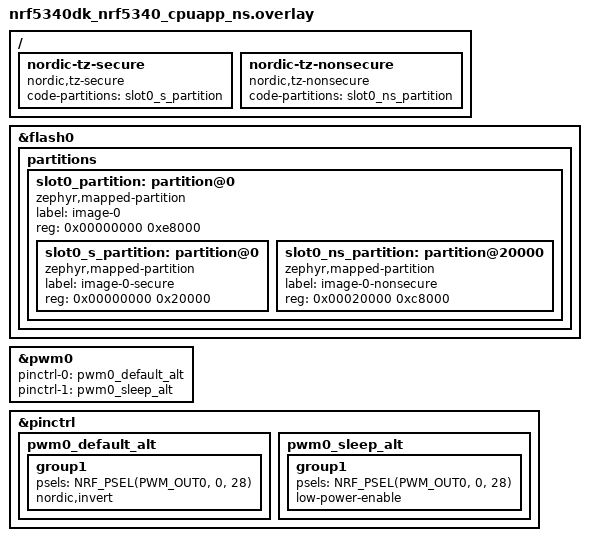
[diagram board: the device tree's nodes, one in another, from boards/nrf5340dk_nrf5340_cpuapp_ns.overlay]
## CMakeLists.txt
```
#
# Copyright (c) 2020 Nordic Semiconductor ASA
#
# SPDX-License-Identifier: LicenseRef-Nordic-5-Clause
#
cmake_minimum_required(VERSION 3.20.0)

find_package(Zephyr REQUIRED HINTS $ENV{ZEPHYR_BASE})
project(bluetooth_mesh_light_ctrl)

# NORDIC SDK APP START
target_sources(app PRIVATE
  src/main.c
  src/model_handler.c
  src/lc_pwm_led.c
)
target_include_directories(app PRIVATE include)
# NORDIC SDK APP END
```

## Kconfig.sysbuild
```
#
# Copyright (c) 2023 Nordic Semiconductor
#
# SPDX-License-Identifier: LicenseRef-Nordic-5-Clause
#

config PARTITION_MANAGER
	default n

config NRF_DEFAULT_IPC_RADIO
	default y

source "share/sysbuild/Kconfig"
```

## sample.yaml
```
sample:
  description: Bluetooth Mesh light fixture sample
  name: Bluetooth Mesh light fixture
common:
  tags:
    - bluetooth
    - ci_build
    - sysbuild
    - ci_samples_bluetooth
tests:
  sample.bluetooth.mesh.light_ctrl:
    sysbuild: true
    build_only: true
    integration_platforms:
      - nrf54l15dk/nrf54l15/cpuapp
    platform_allow:
      - nrf5340dk/nrf5340/cpuapp
      - nrf5340dk/nrf5340/cpuapp/ns
      - nrf54l15dk/nrf54l15/cpuapp
      - nrf54l15dk/nrf54l10/cpuapp
      - nrf54l15dk/nrf54l05/cpuapp
      - nrf54lm20dk/nrf54lm20a/cpuapp
  sample.bluetooth.mesh.light_ctrl.emds:
    sysbuild: true
    build_only: true
    integration_platforms:
      - nrf54l15dk/nrf54l15/cpuapp
    platform_allow:
      - nrf5340dk/nrf5340/cpuapp
      - nrf5340dk/nrf5340/cpuapp/ns
      - nrf54l15dk/nrf54l15/cpuapp
      - nrf54l15dk/nrf54l10/cpuapp
      - nrf54l15dk/nrf54l05/cpuapp
      - nrf54lm20dk/nrf54lm20a/cpuapp
    extra_args: FILE_SUFFIX=emds
  sample.bluetooth.mesh.light_ctrl.settings_ext_flash:
    sysbuild: true
    build_only: true
    integration_platforms:
      - nrf54l15dk/nrf54l15/cpuapp
    platform_allow:
      - nrf54l15dk/nrf54l15/cpuapp
      - nrf54l15dk/nrf54l10/cpuapp
      - nrf54l15dk/nrf54l05/cpuapp
    extra_args: FILE_SUFFIX=settings_ext_flash
```

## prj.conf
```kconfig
#
# Copyright (c) 2020 Nordic Semiconductor ASA
#
# SPDX-License-Identifier: LicenseRef-Nordic-5-Clause
#
CONFIG_NCS_SAMPLES_DEFAULTS=y

# Deferred logging helps improve LPN power consumption
# when friendship is established.
CONFIG_LOG_MODE_DEFERRED=y

# General configuration
CONFIG_NCS_APPLICATION_BOOT_BANNER_STRING="Mesh Light Fixture"
CONFIG_SYSTEM_WORKQUEUE_STACK_SIZE=2048
CONFIG_FLASH=y
CONFIG_FLASH_MAP=y
CONFIG_NVS=y
CONFIG_NVS_LOOKUP_CACHE=y
CONFIG_SETTINGS=y
CONFIG_SETTINGS_NVS_NAME_CACHE=y
CONFIG_HWINFO=y
CONFIG_DK_LIBRARY=y
CONFIG_PWM=y
CONFIG_SOC_FLASH_NRF_PARTIAL_ERASE=y

# Bluetooth configuration
CONFIG_BT=y
CONFIG_BT_DEVICE_NAME="Mesh Light Fixture"
CONFIG_BT_L2CAP_TX_BUF_COUNT=8
CONFIG_BT_OBSERVER=y
CONFIG_BT_PERIPHERAL=y

# Disable unused Bluetooth features
CONFIG_BT_CTLR_LE_ENC=n
CONFIG_BT_PHY_UPDATE=n
CONFIG_BT_CTLR_CHAN_SEL_2=n
CONFIG_BT_CTLR_MIN_USED_CHAN=n
CONFIG_BT_CTLR_PRIVACY=n

# Bluetooth Mesh configuration
CONFIG_BT_MESH=y
CONFIG_BT_MESH_RELAY=y
CONFIG_BT_MESH_FRIEND=y
CONFIG_BT_MESH_TX_SEG_MAX=10
CONFIG_BT_MESH_PB_GATT=y
CONFIG_BT_MESH_PROXY_USE_DEVICE_NAME=y
CONFIG_BT_MESH_GATT_PROXY=y
CONFIG_BT_MESH_ADV_EXT_GATT_SEPARATE=y
CONFIG_BT_MESH_DK_PROV=y
CONFIG_BT_MESH_NLC_PERF_LIGHTNESS_CTRL=y
CONFIG_BT_MESH_NLC_PERF_ENERGY_MONITOR=y
CONFIG_BT_MESH_MODEL_EXTENSIONS=y
CONFIG_BT_MESH_MODEL_EXTENSION_LIST_SIZE=18
# Enabling NLC Lightness Controller profile enables support for 3 application keys by
# default. Therefore, allow up to 3 application key bindings per model instance.
CONFIG_BT_MESH_MODEL_KEY_COUNT=3

# Bluetooth Mesh models
CONFIG_BT_MESH_LIGHT_CTRL_SRV=y
CONFIG_BT_MESH_LIGHT_CTRL_SRV_TIME_ON=3
CONFIG_BT_MESH_LIGHT_CTRL_SRV_TIME_PROLONG=3
CONFIG_BT_MESH_LIGHT_CTRL_SRV_RESUME_DELAY=30
CONFIG_BT_MESH_SCENE_SRV=y
CONFIG_BT_MESH_SENSOR_SRV=y

CONFIG_LTO=y
CONFIG_ISR_TABLES_LOCAL_DECLARATION=y
```

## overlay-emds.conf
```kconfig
#
# Copyright (c) 2022 Nordic Semiconductor ASA
#
# SPDX-License-Identifier: LicenseRef-Nordic-5-Clause
#
CONFIG_EMDS=y
CONFIG_BT_MESH_RPL_STORAGE_MODE_EMDS=y

# MPSL dynamic interrupts required to be able to uninitialize MPSL before
# storing EMDS data.
CONFIG_DYNAMIC_INTERRUPTS=y
CONFIG_DYNAMIC_DIRECT_INTERRUPTS=y
CONFIG_MPSL_DYNAMIC_INTERRUPTS=y

CONFIG_NEW_EMDS=y
CONFIG_EMDS_LOG_LEVEL_DBG=y
CONFIG_PM_PARTITION_SIZE_EMDS_STORAGE=0x4000
```

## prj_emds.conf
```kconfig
#
# Copyright (c) 2026 Nordic Semiconductor ASA
#
# SPDX-License-Identifier: LicenseRef-Nordic-5-Clause
#

CONFIG_NCS_SAMPLES_DEFAULTS=y

# Deferred logging helps improve LPN power consumption
# when friendship is established.
CONFIG_LOG_MODE_DEFERRED=y

# General configuration
CONFIG_NCS_APPLICATION_BOOT_BANNER_STRING="Mesh Light Fixture"
CONFIG_SYSTEM_WORKQUEUE_STACK_SIZE=2048
CONFIG_FLASH=y
CONFIG_FLASH_MAP=y
CONFIG_NVS=y
CONFIG_NVS_LOOKUP_CACHE=y
CONFIG_SETTINGS=y
CONFIG_SETTINGS_NVS_NAME_CACHE=y
CONFIG_HWINFO=y
CONFIG_DK_LIBRARY=y
CONFIG_PWM=y
CONFIG_SOC_FLASH_NRF_PARTIAL_ERASE=y

# Bluetooth configuration
CONFIG_BT=y
CONFIG_BT_DEVICE_NAME="Mesh Light Fixture"
CONFIG_BT_L2CAP_TX_BUF_COUNT=8
CONFIG_BT_OBSERVER=y
CONFIG_BT_PERIPHERAL=y

# Disable unused Bluetooth features
CONFIG_BT_CTLR_LE_ENC=n
CONFIG_BT_PHY_UPDATE=n
CONFIG_BT_CTLR_CHAN_SEL_2=n
CONFIG_BT_CTLR_MIN_USED_CHAN=n
CONFIG_BT_CTLR_PRIVACY=n

# Bluetooth Mesh configuration
CONFIG_BT_MESH=y
CONFIG_BT_MESH_RELAY=y
CONFIG_BT_MESH_FRIEND=y
CONFIG_BT_MESH_TX_SEG_MAX=10
CONFIG_BT_MESH_PB_GATT=y
CONFIG_BT_MESH_PROXY_USE_DEVICE_NAME=y
CONFIG_BT_MESH_GATT_PROXY=y
CONFIG_BT_MESH_ADV_EXT_GATT_SEPARATE=y
CONFIG_BT_MESH_DK_PROV=y
CONFIG_BT_MESH_NLC_PERF_LIGHTNESS_CTRL=y
CONFIG_BT_MESH_NLC_PERF_ENERGY_MONITOR=y
CONFIG_BT_MESH_MODEL_EXTENSIONS=y
CONFIG_BT_MESH_MODEL_EXTENSION_LIST_SIZE=18
# Enabling NLC Lightness Controller profile enables support for 3 application keys by
# default. Therefore, allow up to 3 application key bindings per model instance.
CONFIG_BT_MESH_MODEL_KEY_COUNT=3

# Bluetooth Mesh models
CONFIG_BT_MESH_LIGHT_CTRL_SRV=y
CONFIG_BT_MESH_LIGHT_CTRL_SRV_TIME_ON=3
CONFIG_BT_MESH_LIGHT_CTRL_SRV_TIME_PROLONG=3
CONFIG_BT_MESH_LIGHT_CTRL_SRV_RESUME_DELAY=30
CONFIG_BT_MESH_SCENE_SRV=y
CONFIG_BT_MESH_SENSOR_SRV=y


# EMDS (Emergency Data Storage) configuration
CONFIG_EMDS=y

# MPSL dynamic interrupts required to be able to uninitialize MPSL before
# storing EMDS data.
CONFIG_DYNAMIC_INTERRUPTS=y
CONFIG_DYNAMIC_DIRECT_INTERRUPTS=y
CONFIG_MPSL_DYNAMIC_INTERRUPTS=y

CONFIG_LTO=y
CONFIG_ISR_TABLES_LOCAL_DECLARATION=y
```

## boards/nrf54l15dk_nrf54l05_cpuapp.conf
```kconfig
#
# Copyright (c) 2024 Nordic Semiconductor ASA
#
# SPDX-License-Identifier: LicenseRef-Nordic-5-Clause
#
################################################################################
# Application overlay - nrf54l05

CONFIG_SOC_FLASH_NRF_PARTIAL_ERASE=n
CONFIG_NVS=n
CONFIG_NVS_LOOKUP_CACHE=n
CONFIG_SETTINGS_NVS_NAME_CACHE=n
CONFIG_ZMS=y
CONFIG_SETTINGS_ZMS_CUSTOM_SECTOR_COUNT=y
CONFIG_SETTINGS_ZMS_SECTOR_COUNT=8
CONFIG_ZMS_LOOKUP_CACHE=y
CONFIG_ZMS_LOOKUP_CACHE_SIZE=512
```

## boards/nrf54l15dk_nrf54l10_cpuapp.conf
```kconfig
#
# Copyright (c) 2024 Nordic Semiconductor ASA
#
# SPDX-License-Identifier: LicenseRef-Nordic-5-Clause
#
################################################################################
# Application overlay - nrf54l10

CONFIG_SOC_FLASH_NRF_PARTIAL_ERASE=n
CONFIG_NVS=n
CONFIG_NVS_LOOKUP_CACHE=n
CONFIG_SETTINGS_NVS_NAME_CACHE=n
CONFIG_ZMS=y
CONFIG_SETTINGS_ZMS_SECTOR_COUNT=8
CONFIG_ZMS_LOOKUP_CACHE=y
CONFIG_ZMS_LOOKUP_CACHE_SIZE=512
CONFIG_SETTINGS_ZMS_NAME_CACHE=y
CONFIG_SETTINGS_ZMS_NAME_CACHE_SIZE=512
CONFIG_ZMS_LOOKUP_CACHE_FOR_SETTINGS=y

CONFIG_SYSTEM_WORKQUEUE_STACK_SIZE=4096
CONFIG_BT_RX_STACK_SIZE=5120
```

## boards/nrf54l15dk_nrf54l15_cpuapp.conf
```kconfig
#
# Copyright (c) 2024 Nordic Semiconductor ASA
#
# SPDX-License-Identifier: LicenseRef-Nordic-5-Clause
#
################################################################################
# Application overlay - nrf54l15

CONFIG_SOC_FLASH_NRF_PARTIAL_ERASE=n
CONFIG_NVS=n
CONFIG_NVS_LOOKUP_CACHE=n
CONFIG_SETTINGS_NVS_NAME_CACHE=n
CONFIG_ZMS=y
CONFIG_SETTINGS_ZMS_SECTOR_COUNT=8
CONFIG_ZMS_LOOKUP_CACHE=y
CONFIG_ZMS_LOOKUP_CACHE_SIZE=512
CONFIG_SETTINGS_ZMS_NAME_CACHE=y
CONFIG_SETTINGS_ZMS_NAME_CACHE_SIZE=512
CONFIG_ZMS_LOOKUP_CACHE_FOR_SETTINGS=y

CONFIG_SYSTEM_WORKQUEUE_STACK_SIZE=4096
CONFIG_BT_RX_STACK_SIZE=5120
```

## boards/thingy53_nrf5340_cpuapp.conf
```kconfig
#
# Copyright (c) 2021 Nordic Semiconductor ASA
#
# SPDX-License-Identifier: LicenseRef-Nordic-5-Clause
#
################################################################################
# Application overlay - Thingy:53 DFU

CONFIG_NCS_SAMPLE_MCUMGR_BT_OTA_DFU=y
CONFIG_NCS_SAMPLE_MCUMGR_BT_OTA_DFU_SPEEDUP=y

CONFIG_SYSTEM_WORKQUEUE_STACK_SIZE=4096

# Use deferred logging
CONFIG_NCS_SAMPLES_DEFAULTS=n
CONFIG_LOG=y
CONFIG_ASSERT=y
CONFIG_ASSERT_NO_COND_INFO=y
CONFIG_ASSERT_NO_MSG_INFO=y
CONFIG_HW_STACK_PROTECTION=y

CONFIG_PM_PARTITION_SIZE_SETTINGS_STORAGE=0x8000
```

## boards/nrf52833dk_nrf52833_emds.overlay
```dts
/*
 * Copyright (c) 2026 Nordic Semiconductor ASA
 *
 * SPDX-License-Identifier: LicenseRef-Nordic-5-Clause
 */

/delete-node/ &boot_partition;
/delete-node/ &slot0_partition;
/delete-node/ &slot1_partition;
/delete-node/ &storage_partition;

&flash0 {
	partitions {
		slot0_partition: partition@0 {
			compatible = "zephyr,mapped-partition";
			label = "image-0";
			reg = <0x00000000 0x00070000>;
		};

		storage_partition: partition@70000 {
			compatible = "zephyr,mapped-partition";
			label = "storage";
			reg = <0x00070000 0x00008000>;
		};

		emds_partition_0: partition@78000 {
			compatible = "zephyr,mapped-partition";
			label = "emds-0";
			reg = <0x00078000 0x00004000>;
		};

		emds_partition_1: partition@7c000 {
			compatible = "zephyr,mapped-partition";
			label = "emds-1";
			reg = <0x0007c000 0x00004000>;
		};
	};
};
```

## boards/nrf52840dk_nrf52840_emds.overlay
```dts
/*
 * Copyright (c) 2026 Nordic Semiconductor ASA
 *
 * SPDX-License-Identifier: LicenseRef-Nordic-5-Clause
 */

/delete-node/ &boot_partition;
/delete-node/ &slot0_partition;
/delete-node/ &slot1_partition;
/delete-node/ &storage_partition;

&flash0 {
	partitions {
		slot0_partition: partition@0 {
			compatible = "zephyr,mapped-partition";
			label = "image-0";
			reg = <0x00000000 0x000f0000>;
		};

		storage_partition: partition@f0000 {
			compatible = "zephyr,mapped-partition";
			label = "storage";
			reg = <0x000f0000 0x00008000>;
		};

		emds_partition_0: partition@f8000 {
			compatible = "zephyr,mapped-partition";
			label = "emds-0";
			reg = <0x000f8000 0x00004000>;
		};

		emds_partition_1: partition@fc000 {
			compatible = "zephyr,mapped-partition";
			label = "emds-1";
			reg = <0x000fc000 0x00004000>;
		};
	};
};
```

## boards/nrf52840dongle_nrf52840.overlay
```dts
/*
 * Copyright (c) 2026 Nordic Semiconductor ASA
 *
 * SPDX-License-Identifier: LicenseRef-Nordic-5-Clause
 */

/delete-node/ &boot_partition;
/delete-node/ &slot0_partition;
/delete-node/ &slot1_partition;
/delete-node/ &storage_partition;

&flash0 {
	partitions {
		slot0_partition: partition@1000 {
			compatible = "zephyr,mapped-partition";
			label = "image-0";
			reg = <0x00001000 0x000d7000>;
		};

		storage_partition: partition@d8000 {
			compatible = "zephyr,mapped-partition";
			label = "storage";
			reg = <0x000d8000 0x00008000>;
		};
	};
};
```

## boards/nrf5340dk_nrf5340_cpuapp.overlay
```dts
&pwm0 {
	status = "okay";
	ch0-pin = <28>;
	ch0-inverted;
};
```

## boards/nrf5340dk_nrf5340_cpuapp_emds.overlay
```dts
/*
 * Copyright (c) 2026 Nordic Semiconductor ASA
 *
 * SPDX-License-Identifier: LicenseRef-Nordic-5-Clause
 */

&pwm0 {
	status = "okay";
	pinctrl-0 = <&pwm0_default_alt>;
	pinctrl-1 = <&pwm0_sleep_alt>;
	pinctrl-names = "default", "sleep";
};

&pinctrl {
	pwm0_default_alt: pwm0_default_alt {
		group1 {
			psels = <NRF_PSEL(PWM_OUT0, 0, 28)>;
			nordic,invert;
		};
	};

	pwm0_sleep_alt: pwm0_sleep_alt {
		group1 {
			psels = <NRF_PSEL(PWM_OUT0, 0, 28)>;
			low-power-enable;
		};
	};
};

/delete-node/ &boot_partition;
/delete-node/ &slot0_partition;
/delete-node/ &slot1_partition;
/delete-node/ &storage_partition;

&flash0 {
	partitions {
		slot0_partition: partition@0 {
			compatible = "zephyr,mapped-partition";
			label = "image-0";
			reg = <0x00000000 0x000f0000>;
		};

		storage_partition: partition@f0000 {
			compatible = "zephyr,mapped-partition";
			label = "storage";
			reg = <0x000f0000 0x00008000>;
		};

		emds_partition_0: partition@f8000 {
			compatible = "zephyr,mapped-partition";
			label = "emds-0";
			reg = <0x000f8000 0x00004000>;
		};

		emds_partition_1: partition@fc000 {
			compatible = "zephyr,mapped-partition";
			label = "emds-1";
			reg = <0x000fc000 0x00004000>;
		};
	};
};
```

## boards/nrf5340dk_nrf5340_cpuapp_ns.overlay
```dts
/*
 * Copyright (c) 2026 Nordic Semiconductor ASA
 *
 * SPDX-License-Identifier: LicenseRef-Nordic-5-Clause
 */

/* Rebalance secure/non-secure subpartitions to fit larger mesh sample image.
 * MCUboot is removed; slot0 starts at 0x0 and spans 928 KB (0xe8000).
 * Secure: 128 KB, Non-secure: 800 KB.
 */

/delete-node/ &boot_partition;
/delete-node/ &slot0_partition;

&flash0 {
	partitions {
		slot0_partition: partition@0 {
			compatible = "zephyr,mapped-partition";
			label = "image-0";
			reg = <0x00000000 0xe8000>;
			ranges = <0x0 0x0 0xe8000>;
			#address-cells = <1>;
			#size-cells = <1>;

			slot0_s_partition: partition@0 {
				compatible = "zephyr,mapped-partition";
				label = "image-0-secure";
				reg = <0x00000000 0x20000>;
			};

			slot0_ns_partition: partition@20000 {
				compatible = "zephyr,mapped-partition";
				label = "image-0-nonsecure";
				reg = <0x00020000 0xc8000>;
			};
		};
	};
};

/ {
	/delete-node/ nordic-tz-secure;
	/delete-node/ nordic-tz-nonsecure;

	nordic-tz-secure {
		compatible = "nordic,tz-secure";
		code-partitions = <&slot0_s_partition>;
	};

	nordic-tz-nonsecure {
		compatible = "nordic,tz-nonsecure";
		code-partitions = <&slot0_ns_partition>;
	};
};

&pwm0 {
	status = "okay";
	pinctrl-0 = <&pwm0_default_alt>;
	pinctrl-1 = <&pwm0_sleep_alt>;
	pinctrl-names = "default", "sleep";
};

&pinctrl {
	pwm0_default_alt: pwm0_default_alt {
		group1 {
			psels = <NRF_PSEL(PWM_OUT0, 0, 28)>;
			nordic,invert;
		};
	};

	pwm0_sleep_alt: pwm0_sleep_alt {
		group1 {
			psels = <NRF_PSEL(PWM_OUT0, 0, 28)>;
			low-power-enable;
		};
	};
};
```

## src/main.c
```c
/*
 * Copyright (c) 2020 Nordic Semiconductor ASA
 *
 * SPDX-License-Identifier: LicenseRef-Nordic-5-Clause
 */

/** @file
 *  @brief Nordic mesh light fixture sample
 */
#include <zephyr/logging/log_ctrl.h>
#include <zephyr/bluetooth/bluetooth.h>
#include <bluetooth/mesh/models.h>
#include <bluetooth/mesh/dk_prov.h>
#include <dk_buttons_and_leds.h>
#include "model_handler.h"
#include "lc_pwm_led.h"

#ifdef CONFIG_EMDS
#include <emds/emds.h>

#if defined(CONFIG_HAS_BT_CTLR)
#include <mpsl/mpsl_lib.h>
#endif

#if defined(CONFIG_SOC_SERIES_NRF53)
	#define EMDS_DEV_IRQ EGU1_IRQn
#elif defined(CONFIG_SOC_SERIES_NRF54L)
	#define EMDS_DEV_IRQ SWI01_IRQn
#endif

#define EMDS_DEV_PRIO 0
#define EMDS_ISR_ARG 0
#define EMDS_IRQ_FLAGS 0

static void button_handler_cb(uint32_t pressed, uint32_t changed)
{
	if (pressed & changed & BIT(3)) {
		NVIC_SetPendingIRQ(EMDS_DEV_IRQ);
	}
}

static void app_emds_cb(void)
{
	/* The sample did not call bt_disable and stop the Bluetooth stack properly.
	 * Therefore, the device does not work any longer and needs reboot.
	 */
	/* Flush logs before halting. */
	log_panic();
	dk_set_leds(DK_LED2_MSK | DK_LED3_MSK | DK_LED4_MSK);
	k_fatal_halt(K_ERR_CPU_EXCEPTION);
}

static void isr_emds_cb(void *arg)
{
	ARG_UNUSED(arg);

#if defined(CONFIG_HAS_BT_CTLR)
	/* The sample does not stop the SoftDevice Controller here because the device expects
	 * a system reset after EMDS completes storing.
	 */
	int32_t err = mpsl_lib_uninit();

	if (err != 0) {
		printk("Could not stop MPSL (err %d)\n", err);
	}
#endif

	emds_store();
}
#endif

#ifdef CONFIG_EMDS
static void node_reset_handler(void)
{
	printk("Node reset\n");

	/* Upon node reset, clear the EMDS so that stale RPL data, if any, is removed.
	 *
	 * If you don't want to clear the EMDS data for application specific reasons, you must then
	 * call emds_store() to save the current state of RPL (which is cleared internally by the
	 * system) and that of application specific data, if any. See @ref emds_store() for more
	 * details.
	 */
	int err = emds_clear();

	if (err) {
		printk("EMDS clear failed (err %d)\n", err);
	}
}
#endif

static void bt_ready(int err)
{
	if (err) {
		printk("Bluetooth init failed (err %d)\n", err);
		return;
	}

	printk("Bluetooth initialized\n");

	err = dk_leds_init();
	if (err) {
		printk("Initializing LEDs failed (err %d)\n", err);
		return;
	}

	err = dk_buttons_init(NULL);
	if (err) {
		printk("Initializing buttons failed (err %d)\n", err);
		return;
	}

#ifdef CONFIG_EMDS
	static struct button_handler button_handler = {
		.cb = button_handler_cb,
	};

	dk_button_handler_add(&button_handler);

	err = emds_init(&app_emds_cb);
	if (err) {
		printk("Initializing emds failed (err %d)\n", err);
		return;
	}

	bt_mesh_dk_prov_node_reset_cb_set(node_reset_handler);
#endif

	err = bt_mesh_init(bt_mesh_dk_prov_init(), model_handler_init());
	if (err) {
		printk("Initializing mesh failed (err %d)\n", err);
		return;
	}

#ifdef CONFIG_EMDS
	err = emds_load();
	if (err && err != -ENOENT) {
		printk("Restore of emds data failed (err %d)\n", err);
		return;
	} else if (err == -ENOENT) {
		printk("No valid emds data found, starting fresh\n");
	} else {
		printk("Restored emds data successfully\n");
	}

	err = emds_prepare();
	if (err) {
		printk("Preparation emds failed (err %d)\n", err);
		return;
	}

	IRQ_CONNECT(EMDS_DEV_IRQ, EMDS_DEV_PRIO, isr_emds_cb,
		    EMDS_ISR_ARG, EMDS_IRQ_FLAGS);
	irq_enable(EMDS_DEV_IRQ);
#endif

	if (IS_ENABLED(CONFIG_SETTINGS)) {
		settings_load();
	}

	/* This will be a no-op if settings_load() loaded provisioning info */
	bt_mesh_prov_enable(BT_MESH_PROV_ADV | BT_MESH_PROV_GATT);

	printk("Mesh initialized\n");

	model_handler_start();
}

int main(void)
{
	int err;

	printk("Initializing...\n");
	lc_pwm_led_init();
	err = bt_enable(bt_ready);
	if (err) {
		printk("Bluetooth init failed (err %d)\n", err);
	}

	return 0;
}
```

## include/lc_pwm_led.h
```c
/*
 * Copyright (c) 2020 Nordic Semiconductor ASA
 *
 * SPDX-License-Identifier: LicenseRef-Nordic-5-Clause
 */

/**
 * @file
 * @brief Lc pwm led module
 */

#ifndef LC_PWM_LED_H__
#define LC_PWM_LED_H__

#include <zephyr/types.h>

#ifdef __cplusplus
extern "C" {
#endif

void lc_pwm_led_init(void);

void lc_pwm_led_set(uint16_t desired_lvl);

#ifdef __cplusplus
}
#endif

#endif /* LC_PWM_LED_H__ */
```

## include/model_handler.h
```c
/*
 * Copyright (c) 2020 Nordic Semiconductor ASA
 *
 * SPDX-License-Identifier: LicenseRef-Nordic-5-Clause
 */

/**
 * @file
 * @brief Model handler
 */

#ifndef MODEL_HANDLER_H__
#define MODEL_HANDLER_H__

#include <bluetooth/mesh.h>

#ifdef __cplusplus
extern "C" {
#endif

const struct bt_mesh_comp *model_handler_init(void);
void model_handler_start(void);

#ifdef __cplusplus
}
#endif

#endif /* MODEL_HANDLER_H__ */
```

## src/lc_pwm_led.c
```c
/*
 * Copyright (c) 2020 Nordic Semiconductor ASA
 *
 * SPDX-License-Identifier: LicenseRef-Nordic-5-Clause
 */

#include <bluetooth/mesh/models.h>
#include <dk_buttons_and_leds.h>
#include "model_handler.h"
#include <zephyr/drivers/pwm.h>

#define PWM_LED0_NODE	DT_ALIAS(pwm_led0)

#if DT_NODE_HAS_STATUS(PWM_LED0_NODE, okay)
static const struct pwm_dt_spec led0 = PWM_DT_SPEC_GET(PWM_LED0_NODE);
#else
#error "Unsupported board: pwm-led0 devicetree alias is not defined"
#endif

#define PWM_PERIOD 1024

void lc_pwm_led_init(void)
{
	if (!device_is_ready(led0.dev)) {
		printk("Error: PWM device %s is not ready\n", led0.dev->name);
		return;
	}
}

void lc_pwm_led_set(uint16_t desired_lvl)
{
	uint32_t scaled_lvl =
		(PWM_PERIOD * desired_lvl) /
		BT_MESH_LIGHTNESS_MAX;

	pwm_set_dt(&led0, PWM_USEC(PWM_PERIOD), PWM_USEC(scaled_lvl));
}
```

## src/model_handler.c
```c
/*
 * Copyright (c) 2020 Nordic Semiconductor ASA
 *
 * SPDX-License-Identifier: LicenseRef-Nordic-5-Clause
 */

#include <zephyr/bluetooth/bluetooth.h>
#include <bluetooth/mesh/models.h>
#include <dk_buttons_and_leds.h>
#include "model_handler.h"
#include "lc_pwm_led.h"

#define PWM_SIZE_STEP 512

struct lightness_ctx {
	struct bt_mesh_lightness_srv lightness_srv;
	struct k_work_delayable per_work;
	uint16_t target_lvl;
	uint16_t current_lvl;
	uint32_t time_per;
	uint32_t rem_time;
};

#if IS_ENABLED(CONFIG_BT_MESH_NLC_PERF_BASELINE)
static const uint8_t cmp2_elem_offset1[2] = { 0, 1 };
static const uint8_t cmp2_elem_offset2[1] = { 0 };

static const struct bt_mesh_comp2_record comp_rec[2] = {
	{/* Basic Lightness Controller NLC Profile 1.0.1 */
	.id = BT_MESH_NLC_PROFILE_ID_BASIC_LIGHTNESS_CONTROLLER,
	.version.x = 1,
	.version.y = 0,
	.version.z = 1,
	.elem_offset_cnt = 2,
	.elem_offset = cmp2_elem_offset1,
	.data_len = 0
	},
	{ /* Energy Monitor NLC Profile 1.0.1 */
	.id = BT_MESH_NLC_PROFILE_ID_ENERGY_MONITOR,
	.version.x = 1,
	.version.y = 0,
	.version.z = 1,
	.elem_offset_cnt = 1,
	.elem_offset = cmp2_elem_offset2,
	.data_len = 0
	}
};

static const struct bt_mesh_comp2 comp_p2 = {
	.record_cnt = 2,
	.record = comp_rec
};
#endif

/* Set up a repeating delayed work to blink the DK's LEDs when attention is
 * requested.
 */
static struct k_work_delayable attention_blink_work;
static bool attention;

static void attention_blink(struct k_work *work)
{
	static int idx;
	const uint8_t pattern[] = {
#if DT_NODE_EXISTS(DT_ALIAS(led0))
		BIT(0),
#endif
#if DT_NODE_EXISTS(DT_ALIAS(led1))
		BIT(1),
#endif
#if DT_NODE_EXISTS(DT_ALIAS(led2))
		BIT(2),
#endif
#if DT_NODE_EXISTS(DT_ALIAS(led3))
		BIT(3),
#endif
	};

	if (attention) {
		dk_set_leds(pattern[idx++ % ARRAY_SIZE(pattern)]);
		k_work_reschedule(&attention_blink_work, K_MSEC(30));
	} else {
		dk_set_leds(DK_NO_LEDS_MSK);
	}
}

static void attention_on(const struct bt_mesh_model *mod)
{
	attention = true;
	k_work_reschedule(&attention_blink_work, K_NO_WAIT);
}

static void attention_off(const struct bt_mesh_model *mod)
{
	/* Will stop rescheduling blink timer */
	attention = false;
}

static const struct bt_mesh_health_srv_cb health_srv_cb = {
	.attn_on = attention_on,
	.attn_off = attention_off,
};

static struct bt_mesh_health_srv health_srv = {
	.cb = &health_srv_cb,
};

BT_MESH_HEALTH_PUB_DEFINE(health_pub, 0);

static void start_new_light_trans(const struct bt_mesh_lightness_set *set,
				  struct lightness_ctx *ctx)
{
	uint32_t step_cnt = abs(set->lvl - ctx->current_lvl) / PWM_SIZE_STEP;
	uint32_t time = set->transition ? set->transition->time : 0;
	uint32_t delay = set->transition ? set->transition->delay : 0;

	ctx->target_lvl = set->lvl;
	ctx->time_per = (step_cnt ? time / step_cnt : 0);
	ctx->rem_time = time;
	k_work_reschedule(&ctx->per_work, K_MSEC(delay));

	printk("New light transition-> Lvl: %d, Time: %d, Delay: %d\n",
	       set->lvl, time, delay);
}

static void periodic_led_work(struct k_work *work)
{
	uint16_t clamped_lvl;
	struct lightness_ctx *l_ctx =
		CONTAINER_OF(work, struct lightness_ctx, per_work.work);
	l_ctx->rem_time -= l_ctx->time_per;

	if ((l_ctx->rem_time <= l_ctx->time_per) ||
	    (abs(l_ctx->target_lvl - l_ctx->current_lvl) <= PWM_SIZE_STEP)) {
		struct bt_mesh_lightness_status status = {
			.current = l_ctx->target_lvl,
			.target = l_ctx->target_lvl,
		};

		l_ctx->current_lvl = l_ctx->target_lvl;
		l_ctx->rem_time = 0;

		bt_mesh_lightness_srv_pub(&l_ctx->lightness_srv, NULL, &status);

		goto apply_and_print;
	} else if (l_ctx->target_lvl > l_ctx->current_lvl) {
		l_ctx->current_lvl += PWM_SIZE_STEP;
	} else {
		l_ctx->current_lvl -= PWM_SIZE_STEP;
	}

	k_work_reschedule(&l_ctx->per_work, K_MSEC(l_ctx->time_per));
apply_and_print:
	clamped_lvl = bt_mesh_lightness_clamp(&l_ctx->lightness_srv, l_ctx->current_lvl);
	lc_pwm_led_set(clamped_lvl);
	printk("Current light lvl: %u/65535\n", clamped_lvl);
}

static void light_set(struct bt_mesh_lightness_srv *srv,
		      struct bt_mesh_msg_ctx *ctx,
		      const struct bt_mesh_lightness_set *set,
		      struct bt_mesh_lightness_status *rsp)
{
	struct lightness_ctx *l_ctx =
		CONTAINER_OF(srv, struct lightness_ctx, lightness_srv);

	start_new_light_trans(set, l_ctx);
	rsp->current = l_ctx->rem_time ? l_ctx->current_lvl : l_ctx->target_lvl;
	rsp->target = l_ctx->target_lvl;
	rsp->remaining_time = set->transition ? set->transition->time : 0;
}

static void light_get(struct bt_mesh_lightness_srv *srv,
		      struct bt_mesh_msg_ctx *ctx,
		      struct bt_mesh_lightness_status *rsp)
{
	struct lightness_ctx *l_ctx =
		CONTAINER_OF(srv, struct lightness_ctx, lightness_srv);

	rsp->current = bt_mesh_lightness_clamp(&l_ctx->lightness_srv, l_ctx->current_lvl);
	rsp->target = l_ctx->target_lvl;
	rsp->remaining_time = l_ctx->rem_time;
}

static const struct bt_mesh_lightness_srv_handlers lightness_srv_handlers = {
	.light_set = light_set,
	.light_get = light_get,
};

static struct lightness_ctx my_ctx = {
	.lightness_srv = BT_MESH_LIGHTNESS_SRV_INIT(&lightness_srv_handlers),

};

static int dummy_energy_use;

static int energy_use_get(struct bt_mesh_sensor_srv *srv,
			 struct bt_mesh_sensor *sensor,
			 struct bt_mesh_msg_ctx *ctx,
			 struct bt_mesh_sensor_value *rsp)
{
	/* Report energy usage as dummy value, and increase it by one every time
	 * a get callback is triggered. The logic and hardware for measuring
	 * the actual energy usage of the device should be implemented here.
	 */
	(void)bt_mesh_sensor_value_from_micro(sensor->type->channels[0].format,
					      dummy_energy_use * 1000000LL, rsp);
	dummy_energy_use++;

	return 0;
}

static const struct bt_mesh_sensor_descriptor energy_use_desc = {
	.tolerance = {
		.negative = 0,
		.positive = 0,
	},
	.sampling_type = BT_MESH_SENSOR_SAMPLING_UNSPECIFIED,
	.period = 0,
	.update_interval = 0,
};

static struct bt_mesh_sensor energy_use = {
	.type = &bt_mesh_sensor_precise_tot_dev_energy_use,
	.get = energy_use_get,
	.descriptor = &energy_use_desc,
};

static struct bt_mesh_sensor *const sensors[] = {
	&energy_use,
};

static struct bt_mesh_sensor_srv sensor_srv =
	BT_MESH_SENSOR_SRV_INIT(sensors, ARRAY_SIZE(sensors));

static struct bt_mesh_scene_srv scene_srv;

static struct bt_mesh_light_ctrl_srv light_ctrl_srv =
	BT_MESH_LIGHT_CTRL_SRV_INIT(&my_ctx.lightness_srv);

static struct bt_mesh_elem elements[] = {
	BT_MESH_ELEM(1,
		     BT_MESH_MODEL_LIST(
			     BT_MESH_MODEL_CFG_SRV,
			     BT_MESH_MODEL_HEALTH_SRV(&health_srv, &health_pub),
			     BT_MESH_MODEL_LIGHTNESS_SRV(
					 &my_ctx.lightness_srv),
			     BT_MESH_MODEL_SCENE_SRV(&scene_srv),
			     BT_MESH_MODEL_SENSOR_SRV(&sensor_srv)),
		     BT_MESH_MODEL_NONE),
	BT_MESH_ELEM(2,
		     BT_MESH_MODEL_LIST(
			     BT_MESH_MODEL_LIGHT_CTRL_SRV(&light_ctrl_srv)),
		     BT_MESH_MODEL_NONE),
};

static const struct bt_mesh_comp comp = {
	.cid = CONFIG_BT_COMPANY_ID,
	.elem = elements,
	.elem_count = ARRAY_SIZE(elements),
};

const struct bt_mesh_comp *model_handler_init(void)
{
	k_work_init_delayable(&attention_blink_work, attention_blink);
	k_work_init_delayable(&my_ctx.per_work, periodic_led_work);

	return &comp;
}

void model_handler_start(void)
{
	int err;

#if IS_ENABLED(CONFIG_BT_MESH_NLC_PERF_BASELINE)
	if (bt_mesh_comp2_register(&comp_p2)) {
		printk("Failed to register comp2\n");
	}
#endif

	if (bt_mesh_is_provisioned()) {
		return;
	}

	bt_mesh_ponoff_srv_set(&light_ctrl_srv.lightness->ponoff,
			       BT_MESH_ON_POWER_UP_RESTORE);

	err = bt_mesh_light_ctrl_srv_enable(&light_ctrl_srv);
	if (!err) {
		printk("Successfully enabled LC server\n");
	}
}
```
